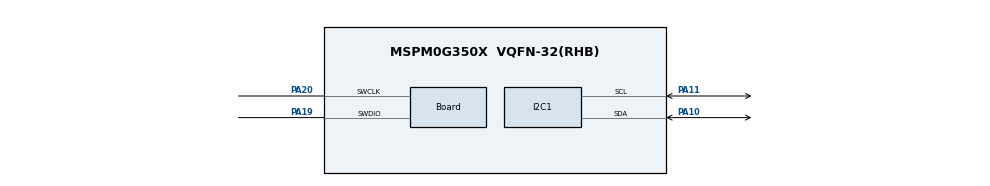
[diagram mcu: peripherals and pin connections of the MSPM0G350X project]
/**
 * @cliArgs --device "MSPM0G350X" --part "Default" --package "VQFN-32(RHB)" --product "mspm0_sdk@2.04.00.06"
 * @versions {"tool":"1.23.0+4000"}
 */

/**
 * Import the modules used in this configuration.
 */
const CRC    = scripting.addModule("/ti/driverlib/CRC");
const EVENT  = scripting.addModule("/ti/driverlib/EVENT");
const GPIO   = scripting.addModule("/ti/driverlib/GPIO", {}, false);
const GPIO1  = GPIO.addInstance();
const I2C    = scripting.addModule("/ti/driverlib/I2C", {}, false);
const I2C1   = I2C.addInstance();
const SYSCTL = scripting.addModule("/ti/driverlib/SYSCTL");

/**
 * Write custom configuration values to the imported modules.
 */
CRC.polynomial = "16_POLYNOMIAL";
CRC.seed       = 0xFFFF;

const Board                       = scripting.addModule("/ti/driverlib/Board", {}, false);
Board.peripheral.$assign          = "DEBUGSS";
Board.peripheral.swclkPin.$assign = "PA20";
Board.peripheral.swdioPin.$assign = "PA19";

GPIO1.$name                              = "LED1";
GPIO1.associatedPins[0].$name            = "PIN_1";
GPIO1.associatedPins[0].internalResistor = "PULL_DOWN";

I2C1.$name                     = "I2C_0";
I2C1.basicEnableController     = true;
I2C1.basicControllerBusSpeed   = 400000;
I2C1.advControllerTXFIFOTRIG   = "BYTES_1";
I2C1.intController             = ["ARBITRATION_LOST","NACK","RXFIFO_TRIGGER","RX_DONE","TX_DONE"];
I2C1.peripheral.$assign        = "I2C0";
I2C1.peripheral.sdaPin.$assign = "PA10";
I2C1.peripheral.sclPin.$assign = "PA11";
I2C1.sdaPinConfig.$name        = "ti_driverlib_gpio_GPIOPinGeneric0";
I2C1.sclPinConfig.$name        = "ti_driverlib_gpio_GPIOPinGeneric1";
I2C1.sclPinConfig.enableConfig = true;

SYSCTL.forceDefaultClkConfig = true;
SYSCTL.clockTreeEn           = true;

const ProjectConfig              = scripting.addModule("/ti/project_config/ProjectConfig", {}, false);
ProjectConfig.migrationCondition = true;

/**
 * Pinmux solution for unlocked pins/peripherals. This ensures that minor changes to the automatic solver in a future
 * version of the tool will not impact the pinmux you originally saw.  These lines can be completely deleted in order to
 * re-solve from scratch.
 */
GPIO1.associatedPins[0].pin.$suggestSolution = "PA0";
